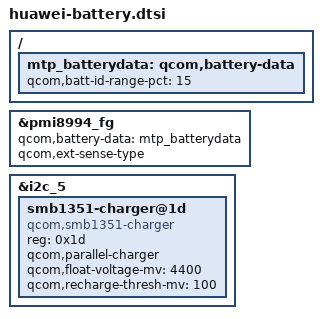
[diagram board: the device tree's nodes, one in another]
/{
	mtp_batterydata: qcom,battery-data {
		qcom,batt-id-range-pct = <15>;
		#include "batterydata-itech-3000mah.dtsi"
	};
};

&pmi8994_fg {
	qcom,battery-data = <&mtp_batterydata>;
	qcom,ext-sense-type;
};

&i2c_5 {
	smb1351-charger@1d {
		compatible = "qcom,smb1351-charger";
		reg = <0x1d>;
		qcom,parallel-charger;
		qcom,float-voltage-mv = <4400>;
		qcom,recharge-thresh-mv = <100>;
	};
};
